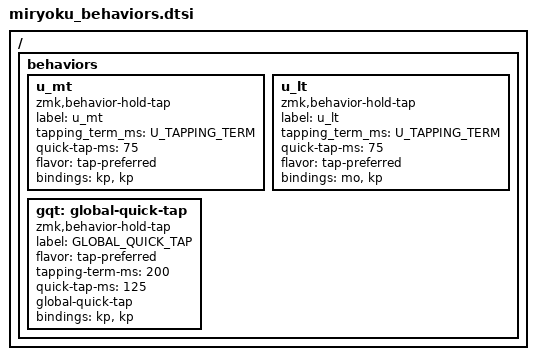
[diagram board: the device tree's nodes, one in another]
// Copyright 2022 Manna Harbour
// https://github.com/manna-harbour/miryoku

/ {
  behaviors {
    u_mt: u_mt {
      compatible = "zmk,behavior-hold-tap";
      label = "u_mt";
      #binding-cells = <2>;
      tapping_term_ms = <U_TAPPING_TERM>;
      quick-tap-ms = <75>;
      flavor = "tap-preferred";
      bindings = <&kp>, <&kp>;
    };
    u_lt: u_lt {
      compatible = "zmk,behavior-hold-tap";
      label = "u_lt";
      #binding-cells = <2>;
      tapping_term_ms = <U_TAPPING_TERM>;
      quick-tap-ms = <75>;
      flavor = "tap-preferred";
      bindings = <&mo>, <&kp>;
    };
    gqt: global-quick-tap {
      compatible = "zmk,behavior-hold-tap";
      label = "GLOBAL_QUICK_TAP";
      #binding-cells = <2>;
      flavor = "tap-preferred";
      tapping-term-ms = <200>;
      quick-tap-ms = <125>;
      global-quick-tap;
      bindings = <&kp>, <&kp>;
    };
  };
};
